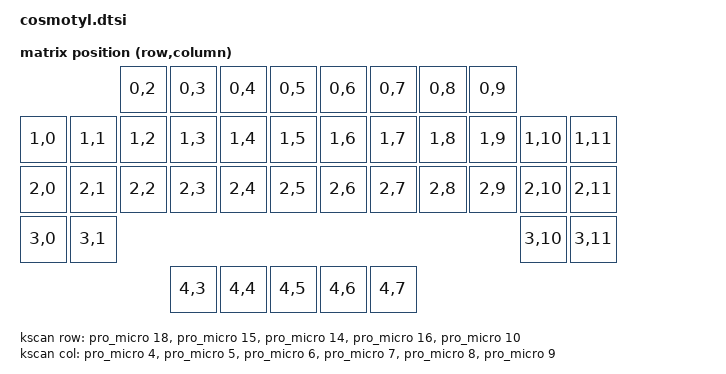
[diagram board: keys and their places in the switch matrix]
// This file was generated from a template. Edit it to match your keyboard.
// See https://zmk.dev/docs/development/hardware-integration/new-shield for more
// instructions.

#include <dt-bindings/zmk/matrix_transform.h>

#include "cosmotyl-layouts.dtsi"

/ {

    kscan: kscan {
        // If the hardware does not use a switch matrix, change this to the
        // appropriate driver and update the properties below to match.
        // See https://zmk.dev/docs/config/kscan for supported key scan drivers.
        compatible = "zmk,kscan-gpio-matrix";
        // Set this to "col2row" or "row2col" to match the hardware. If using
        // "row2col", change the col-gpios in the _left.overlay and
        // _right.overlay files to (GPIO_ACTIVE_HIGH | GPIO_PULL_DOWN) and the
        // row-gpios here to GPIO_ACTIVE_HIGH.
        diode-direction = "col2row";
        wakeup-source;

        /* Columns: C0–C5 */
        col-gpios = <&pro_micro 4 GPIO_ACTIVE_HIGH>,
              <&pro_micro 5 GPIO_ACTIVE_HIGH>,
              <&pro_micro 6 GPIO_ACTIVE_HIGH>,
              <&pro_micro 7 GPIO_ACTIVE_HIGH>,
              <&pro_micro 8 GPIO_ACTIVE_HIGH>,
              <&pro_micro 9 GPIO_ACTIVE_HIGH>;

        /* Rows: R0–R4 */
        row-gpios = 
              <&pro_micro 18 (GPIO_ACTIVE_HIGH | GPIO_PULL_DOWN)>,
              <&pro_micro 15 (GPIO_ACTIVE_HIGH | GPIO_PULL_DOWN)>,
              <&pro_micro 14 (GPIO_ACTIVE_HIGH | GPIO_PULL_DOWN)>,
              <&pro_micro 16 (GPIO_ACTIVE_HIGH | GPIO_PULL_DOWN)>,
              <&pro_micro 10 (GPIO_ACTIVE_HIGH | GPIO_PULL_DOWN)>;
    };

    default_transform: default_transform {
        compatible = "zmk,matrix-transform";
        columns = <12>;
        rows = <5>;

        map = <
                           RC(0, 2) RC(0, 3) RC(0, 4) RC(0, 5)    RC(0, 6) RC(0, 7) RC(0, 8) RC(0, 9)
         RC(1, 0) RC(1, 1) RC(1, 2) RC(1, 3) RC(1, 4) RC(1, 5)    RC(1, 6) RC(1, 7) RC(1, 8) RC(1, 9) RC(1,10) RC(1,11)
         RC(2, 0) RC(2, 1) RC(2, 2) RC(2, 3) RC(2, 4) RC(2, 5)    RC(2, 6) RC(2, 7) RC(2, 8) RC(2, 9) RC(2,10) RC(2,11)
         RC(3, 0) RC(3, 1)                                                                            RC(3,10) RC(3,11)
                                    RC(4, 3) RC(4, 4) RC(4, 5)    RC(4, 6) RC(4, 7)                                    
        >;
    };
};
